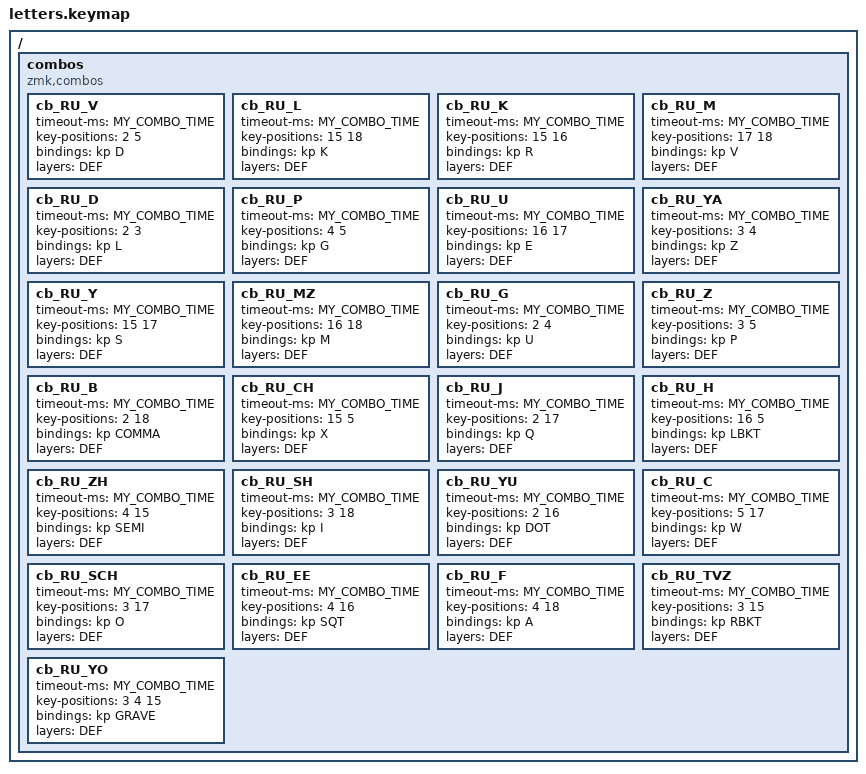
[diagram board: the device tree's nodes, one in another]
/ {
    combos {
        compatible = "zmk,combos";
        cb_RU_V {
            timeout-ms = <MY_COMBO_TIME>;
            key-positions = <2 5>;
            bindings = <&kp D>;
            layers = <DEF>;
        };
        cb_RU_L {
            timeout-ms = <MY_COMBO_TIME>;
            key-positions = <15 18>;
            bindings = <&kp K>;
            layers = <DEF>;
        };
        cb_RU_K {
            timeout-ms = <MY_COMBO_TIME>;
            key-positions = <15 16>;
            bindings = <&kp R>;
            layers = <DEF>;
        };
        cb_RU_M {
            timeout-ms = <MY_COMBO_TIME>;
            key-positions = <17 18>;
            bindings = <&kp V>;
            layers = <DEF>;
        };
        cb_RU_D {
            timeout-ms = <MY_COMBO_TIME>;
            key-positions = <2 3>;
            bindings = <&kp L>;
            layers = <DEF>;
        };
        cb_RU_P {
            timeout-ms = <MY_COMBO_TIME>;
            key-positions = <4 5>;
            bindings = <&kp G>;
            layers = <DEF>;
        };
        cb_RU_U {
            timeout-ms = <MY_COMBO_TIME>;
            key-positions = <16 17>;
            bindings = <&kp E>;
            layers = <DEF>;
        };
        cb_RU_YA {
            timeout-ms = <MY_COMBO_TIME>;
            key-positions = <3 4>;
            bindings = <&kp Z>;
            layers = <DEF>;
        };
        cb_RU_Y {
            timeout-ms = <MY_COMBO_TIME>;
            key-positions = <15 17>;
            bindings = <&kp S>;
            layers = <DEF>;
        };
        cb_RU_MZ {
            timeout-ms = <MY_COMBO_TIME>;
            key-positions = <16 18>;
            bindings = <&kp M>;
            layers = <DEF>;
        };
        cb_RU_G {
            timeout-ms = <MY_COMBO_TIME>;
            key-positions = <2 4>;
            bindings = <&kp U>;
            layers = <DEF>;
        };
        cb_RU_Z {
            timeout-ms = <MY_COMBO_TIME>;
            key-positions = <3 5>;
            bindings = <&kp P>;
            layers = <DEF>;
        };
        cb_RU_B {
            timeout-ms = <MY_COMBO_TIME>;
            key-positions = <2 18>;
            bindings = <&kp COMMA>;
            layers = <DEF>;
        };
        cb_RU_CH {
            timeout-ms = <MY_COMBO_TIME>;
            key-positions = <15 5>;
            bindings = <&kp X>;
            layers = <DEF>;
        };
        cb_RU_J {
            timeout-ms = <MY_COMBO_TIME>;
            key-positions = <2 17>;
            bindings = <&kp Q>;
            layers = <DEF>;
        };
        cb_RU_H {
            timeout-ms = <MY_COMBO_TIME>;
            key-positions = <16 5>;
            bindings = <&kp LBKT>;
            layers = <DEF>;
        };
        cb_RU_ZH {
            timeout-ms = <MY_COMBO_TIME>;
            key-positions = <4 15>;
            bindings = <&kp SEMI>;
            layers = <DEF>;
        };
        cb_RU_SH {
            timeout-ms = <MY_COMBO_TIME>;
            key-positions = <3 18>;
            bindings = <&kp I>;
            layers = <DEF>;
        };
        cb_RU_YU {
            timeout-ms = <MY_COMBO_TIME>;
            key-positions = <2 16>;
            bindings = <&kp DOT>;
            layers = <DEF>;
        };
        cb_RU_C {
            timeout-ms = <MY_COMBO_TIME>;
            key-positions = <5 17>;
            bindings = <&kp W>;
            layers = <DEF>;
        };
        cb_RU_SCH {
            timeout-ms = <MY_COMBO_TIME>;
            key-positions = <3 17>;
            bindings = <&kp O>;
            layers = <DEF>;
        };
        cb_RU_EE {
            timeout-ms = <MY_COMBO_TIME>;
            key-positions = <4 16>;
            bindings = <&kp SQT>;
            layers = <DEF>;
        };
        cb_RU_F {
            timeout-ms = <MY_COMBO_TIME>;
            key-positions = <4 18>;
            bindings = <&kp A>;
            layers = <DEF>;
        };
        cb_RU_TVZ {
            timeout-ms = <MY_COMBO_TIME>;
            key-positions = <3 15>;
            bindings = <&kp RBKT>;
            layers = <DEF>;
        };
        cb_RU_YO {
            timeout-ms = <MY_COMBO_TIME>;
            key-positions = <3 4 15>;
            bindings = <&kp GRAVE>;
            layers = <DEF>;
        };
    };
};
